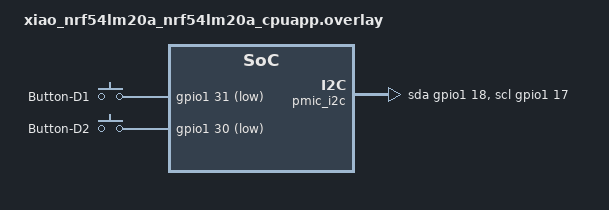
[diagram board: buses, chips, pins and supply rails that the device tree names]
#include <zephyr/dt-bindings/gpio/gpio.h>

&pmic_i2c {
	sda-gpios = <&gpio1 18 GPIO_ACTIVE_HIGH>;
	scl-gpios = <&gpio1 17 GPIO_ACTIVE_HIGH>;
};

npm1300_ek_pmic: &pmic {
};

npm1300_ek_charger: &pmic_charger {
	vbus-limit-microamp = <1500000>;
};

/ {
	aliases {
		button1 = &button1_node;
		button2 = &button2_node;
	};

	buttons {
		compatible = "gpio-keys";

		button1_node: button_1 {
			gpios = <&gpio1 31 (GPIO_PULL_UP | GPIO_ACTIVE_LOW)>;
			label = "Button-D1";
		};

		button2_node: button_2 {
			gpios = <&gpio1 30 (GPIO_PULL_UP | GPIO_ACTIVE_LOW)>;
			label = "Button-D2";
		};
	};
};
